# ESP32-S2 register map
Vendor: ESPRESSIF SYSTEMS (SHANGHAI) CO., LTD.; Series: ESP32 S-Series; File version: 20
CPU: Xtensa LX7 r0p0, little endian, no MPU, no FPU, 0 interrupt priority bits
Address unit: 32 bits
Registers are 32-bit, read-write, reset 0x0 unless marked. A register's access mark holds for its fields unless they carry their own. Offsets are from the block's base; [hi:lo] are bit positions; lines under a group give offsets from that group; {n}, {i} and the like mark numbered series.

## LEDC — LED Control PWM (Pulse Width Modulation)
Base 0x3F419000
{0x0+0x14*i} CH{i} (i=0..7) group — Cluster CH{i}, containing CH?_CONF0, CH?_HPOINT, CH?_DUTY, CH?_CONF1, CH?_DUTY_R
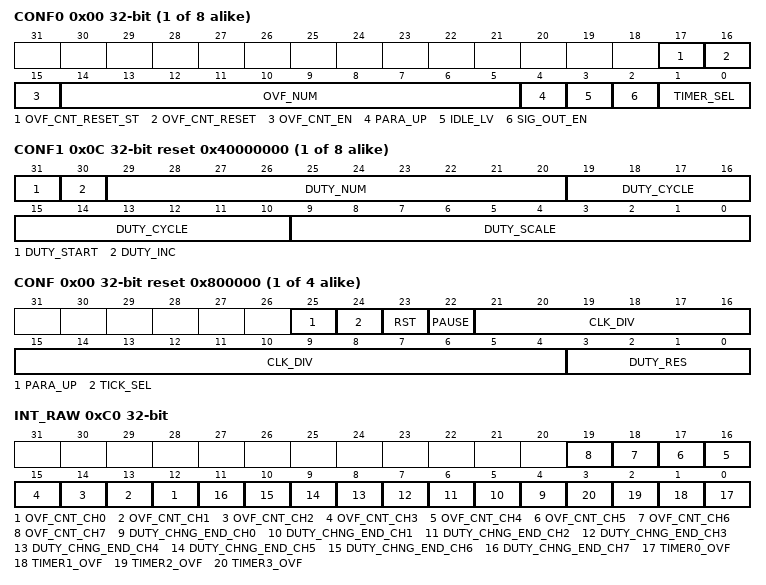
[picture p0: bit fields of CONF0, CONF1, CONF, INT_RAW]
  0x00 CONF0 access per field — Configuration register 0 for channel 0
    [17] OVF_CNT_RESET_ST ro — This is the status bit of LEDC_OVF_CNT_RESET_CH%s.
    [16] OVF_CNT_RESET wo — Set this bit to reset the ovf_cnt of channel %s.
    [15] OVF_CNT_EN rw — This bit is used to enable the ovf_cnt of channel %s.
    [14:5] OVF_NUM rw — This register is used to configure the maximum times of overflow minus 1. The LEDC_OVF_CNT_CH%s_INT interrupt will be triggered when channel %s overflows for (LEDC_OVF_NUM_CH%s + 1) times.
    [4] PARA_UP wo — This bit is used to update register LEDC_CH%s_HPOINT and LEDC_CH%s_DUTY for channel %s.
    [3] IDLE_LV rw — This bit is used to control the output value when channel %s is inactive.
    [2] SIG_OUT_EN rw — Set this bit to enable signal output on channel %s.
    [1:0] TIMER_SEL rw — This field is used to select one of timers for channel %s. 0: select timer 0. 1: select timer 1. 2: select timer 2. 3: select timer 3.
  0x04 HPOINT — High point register for channel 0
    [13:0] HPOINT — The output value changes to high when the selected timers has reached the value specified by this register.
  0x08 DUTY — Initial duty cycle for channel 0
    [18:0] DUTY — This register is used to change the output duty by controlling the Lpoint. The output value turns to low when the selected timers has reached the Lpoint.
  0x0C CONF1 reset 0x40000000 — Configuration register 1 for channel 0
    [31] DUTY_START — Other configured fields in LEDC_CH%s_CONF1_REG will start to take effect when this bit is set to 1.
    [30] DUTY_INC — This register is used to increase or decrease the duty of output signal on channel %s. 1: Increase. 0: Decrease.
    [29:20] DUTY_NUM — This register is used to control the number of times the duty cycle will be changed.
    [19:10] DUTY_CYCLE — The duty will change every LEDC_DUTY_CYCLE_CH%s on channel %s.
    [9:0] DUTY_SCALE — This register is used to configure the changing step scale of duty on channel %s.
  0x10 DUTY_R ro — Current duty cycle for channel 0
    [18:0] DUTY_R — This register stores the current duty of output signal on channel %s.
{0xA0+8i} TIMER{i} (i=0..3) group — Cluster TIMER{i}, containing TIMER?_CONF, TIMER?_VALUE
  0x00 CONF access per field reset 0x800000 — Timer 0 configuration
    [25] PARA_UP wo — Set this bit to update LEDC_CLK_DIV_TIMER%s and LEDC_TIMER%s_DUTY_RES.
    [24] TICK_SEL rw — This bit is used to select clock for timer %s. When this bit is set to 1 LEDC_APB_CLK_SEL[1:0] should be 1, otherwise the timer clock may be not accurate. 0: LEDC_PWM_CLK. 1: REF_TICK.
    [23] RST rw — This bit is used to reset timer %s. The counter will show 0 after reset.
    [22] PAUSE rw — This bit is used to suspend the counter in timer %s.
    [21:4] CLK_DIV rw — This register is used to configure the divisor for the divider in timer %s. The least significant eight bits represent the fractional part.
    [3:0] DUTY_RES rw — This register is used to control the range of the counter in timer %s.
  0x04 VALUE ro — Timer 0 current counter value
    [13:0] CNT — This register stores the current counter value of timer %s.
0xC0 INT_RAW — Raw interrupt status
  [n+12] OVF_CNT_CH{n} (n=0..7) — Interrupt raw bit for channel {n}. Triggered when the OVF_CNT has reached the value specified by LEDC.CHx.CONF0.OVF_NUM.
  [n+4] DUTY_CHNG_END_CH{n} (n=0..7) — Interrupt raw bit for channel {n}. Triggered when the gradual change of duty has finished.
  [n] TIMER{n}_OVF (n=0..3) — Triggered when the timer{n} has reached its maximum counter value.
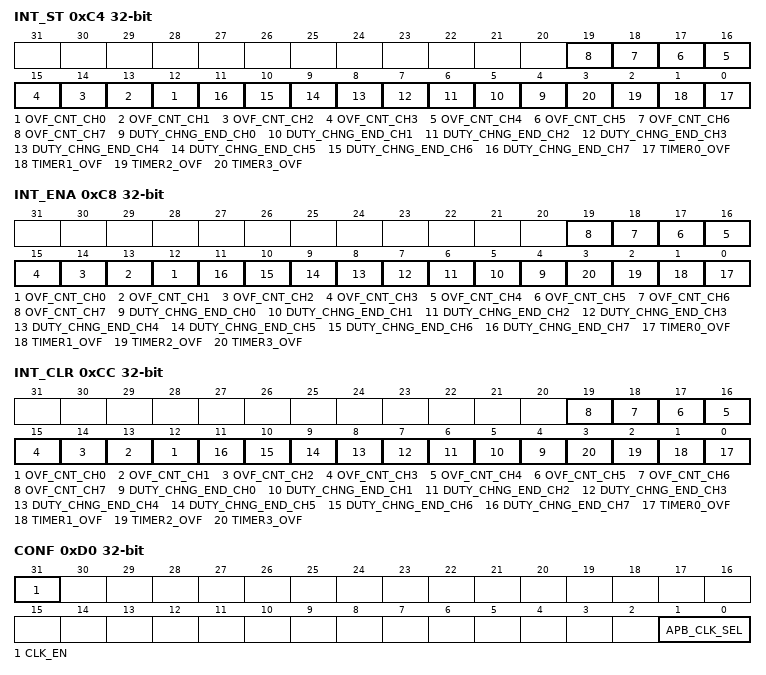
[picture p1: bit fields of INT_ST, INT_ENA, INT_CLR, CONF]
0xC4 INT_ST ro — Masked interrupt status
  [n+12] OVF_CNT_CH{n} (n=0..7) — This is the masked interrupt status bit for the LEDC.INT_RAW.OVF_CNT_CH{n} interrupt when LEDC.INT_ENA.OVF_CNT_CHx is set to 1.
  [n+4] DUTY_CHNG_END_CH{n} (n=0..7) — This is the masked interrupt status bit for the DUTY_CHNG_END_CH{n} interrupt when LEDC.INT_ENA.DUTY_CHNG_END_CHx is set to 1.
  [n] TIMER{n}_OVF (n=0..3) — This is the masked interrupt status bit for the TIMER{n}_OVF interrupt when LEDC.INT_ENA.TIMERx_OVF is set to 1.
0xC8 INT_ENA — Interrupt enable bits
  [n+12] OVF_CNT_CH{n} (n=0..7) — The interrupt enable bit for the OVF_CNT_CH{n} interrupt.
  [n+4] DUTY_CHNG_END_CH{n} (n=0..7) — The interrupt enable bit for the DUTY_CHNG_END_CH{n} interrupt.
  [n] TIMER{n}_OVF (n=0..3) — The interrupt enable bit for the TIMER{n}_OVF interrupt.
0xCC INT_CLR wo — Interrupt clear bits
  [n+12] OVF_CNT_CH{n} (n=0..7) write-1-clears — Set this bit to clear the OVF_CNT_CH{n} interrupt.
  [n+4] DUTY_CHNG_END_CH{n} (n=0..7) write-1-clears — Set this bit to clear the DUTY_CHNG_END_CH{n} interrupt.
  [n] TIMER{n}_OVF (n=0..3) write-1-clears — Set this bit to clear the TIMER{n}_OVF interrupt.
0xD0 CONF — Global ledc configuration register
  [31] CLK_EN — This bit is used to control clock. 1: Force clock on for register. 0: Support clock only when application writes registers.
  [1:0] APB_CLK_SEL — This bit is used to select clock source for the 4 timers . 1: APB_CLK. 2: RTC8M_CLK. 3: XTAL_CLK.
0xFC DATE — Version control register
